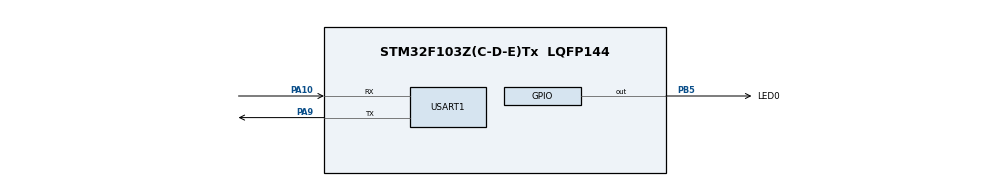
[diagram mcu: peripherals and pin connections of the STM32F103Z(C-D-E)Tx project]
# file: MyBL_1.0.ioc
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Mcu.Family=STM32F1
Mcu.Name=STM32F103Z(C-D-E)Tx
Mcu.Package=LQFP144
NVIC.PriorityGroup=NVIC_PRIORITYGROUP_2
NVIC.USART1_IRQn=true\:3\:3\:true\:false\:true\:true\:true\:true
PA10.Mode=Asynchronous
PA10.Signal=USART1_RX
PA13.Mode=Serial_Wire
PA13.Signal=SYS_JTMS-SWDIO
PA14.Mode=Serial_Wire
PA14.Signal=SYS_JTCK-SWCLK
PA9.Mode=Asynchronous
PA9.Signal=USART1_TX
PB5.GPIO_Label=LED0
PB5.GPIO_ModeDefaultOutputPP=GPIO_MODE_OUTPUT_PP
PB5.GPIO_Speed=GPIO_SPEED_FREQ_HIGH
PB5.PinState=GPIO_PIN_SET
PB5.Signal=GPIO_Output
ProjectManager.HeapSize=0x200
ProjectManager.StackSize=0x400
ProjectManager.TargetToolchain=MDK-ARM V5.32
RCC.APB1Freq_Value=8000000
RCC.APB2Freq_Value=8000000
USART1.VirtualMode=VM_ASYNC
board=custom

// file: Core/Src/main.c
/* USER CODE BEGIN Header */
/**
  ******************************************************************************
  * @file           : main.c
  * @brief          : Main program body
  ******************************************************************************
  * @attention
  *
  * Copyright (c) 2024 STMicroelectronics.
  * All rights reserved.
  *
  * This software is licensed under terms that can be found in the LICENSE file
  * in the root directory of this software component.
  * If no LICENSE file comes with this software, it is provided AS-IS.
  *
  ******************************************************************************
  */
/* USER CODE END Header */
#include "main.h"
#include "usart.h"
#include "gpio.h"
#include <stdio.h>

void SystemClock_Config(void);

/* USER CODE BEGIN 0 */

int fputc(int c, FILE *stream)    //重写fputc函数
{
 /*
    huart1是工具生成代码定义的UART1结构体，
    如果以后要使用其他串口打印，只需要把这个结构体改成其他UART结构体。
*/
    HAL_UART_Transmit(&huart1, (unsigned char *)&c, 1, 1000);
    return 1;
}
/* USER CODE END 0 */

int main(void)
{

  /* MCU Configuration--------------------------------------------------------*/

  /* Reset of all peripherals, Initializes the Flash interface and the Systick. */
  HAL_Init();

  /* Configure the system clock */
  SystemClock_Config();

  /* Initialize all configured peripherals */
  MX_GPIO_Init();
  MX_USART1_UART_Init();
  /* USER CODE BEGIN 2 */
//  HAL_GPIO_TogglePin(LED0_GPIO_Port, LED0_Pin);
//  HAL_GPIO_TogglePin(LED0_GPIO_Port, LED0_Pin);
  HAL_GPIO_WritePin(LED0_GPIO_Port, LED0_Pin, GPIO_PIN_RESET);
//  HAL_GPIO_WritePin(LED0_GPIO_Port, LED0_Pin, GPIO_PIN_SET);
  /* USER CODE END 2 */

  /* Infinite loop */
  while (1)
  {
	HAL_GPIO_TogglePin(LED0_GPIO_Port, LED0_Pin);
	HAL_Delay(1000);
	printf("hello\r\n");
  }
}

void SystemClock_Config(void)
{
  RCC_OscInitTypeDef RCC_OscInitStruct = {0};
  RCC_ClkInitTypeDef RCC_ClkInitStruct = {0};

  /** Initializes the RCC Oscillators according to the specified parameters
  * in the RCC_OscInitTypeDef structure.
  */
  RCC_OscInitStruct.OscillatorType = RCC_OSCILLATORTYPE_HSI;
  RCC_OscInitStruct.HSIState = RCC_HSI_ON;
  RCC_OscInitStruct.HSICalibrationValue = RCC_HSICALIBRATION_DEFAULT;
  RCC_OscInitStruct.PLL.PLLState = RCC_PLL_NONE;
  if (HAL_RCC_OscConfig(&RCC_OscInitStruct) != HAL_OK)
  {
    Error_Handler();
  }

  /** Initializes the CPU, AHB and APB buses clocks
  */
  RCC_ClkInitStruct.ClockType = RCC_CLOCKTYPE_HCLK|RCC_CLOCKTYPE_SYSCLK
                              |RCC_CLOCKTYPE_PCLK1|RCC_CLOCKTYPE_PCLK2;
  RCC_ClkInitStruct.SYSCLKSource = RCC_SYSCLKSOURCE_HSI;
  RCC_ClkInitStruct.AHBCLKDivider = RCC_SYSCLK_DIV1;
  RCC_ClkInitStruct.APB1CLKDivider = RCC_HCLK_DIV1;
  RCC_ClkInitStruct.APB2CLKDivider = RCC_HCLK_DIV1;

  if (HAL_RCC_ClockConfig(&RCC_ClkInitStruct, FLASH_LATENCY_0) != HAL_OK)
  {
    Error_Handler();
  }
}

void Error_Handler(void)
{
  __disable_irq();
  while (1)
  {
  }
}
